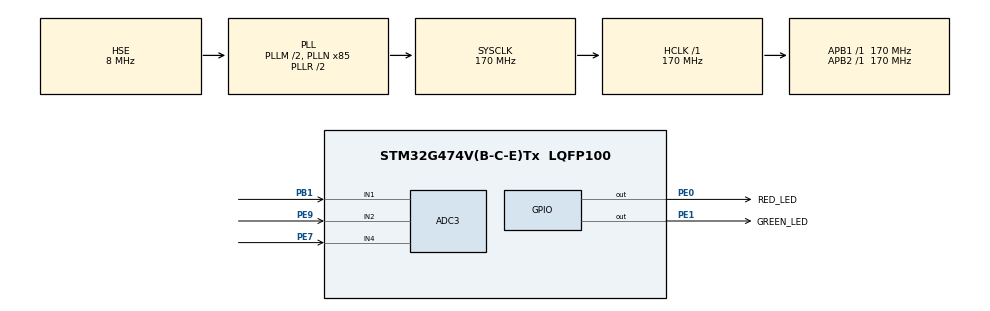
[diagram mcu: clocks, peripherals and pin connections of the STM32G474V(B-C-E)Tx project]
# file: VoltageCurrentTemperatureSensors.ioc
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ADC3.Channel-0\#ChannelRegularConversion=ADC_CHANNEL_1
ADC3.Channel-1\#ChannelRegularConversion=ADC_CHANNEL_1
ADC3.Channel-2\#ChannelRegularConversion=ADC_CHANNEL_1
ADC3.DMAContinuousRequests=ENABLE
ADC3.NbrOfConversion=3
ADC3.NbrOfConversionFlag=1
ADC3.OffsetNumber-0\#ChannelRegularConversion=ADC_OFFSET_NONE
ADC3.OffsetNumber-1\#ChannelRegularConversion=ADC_OFFSET_NONE
ADC3.OffsetNumber-2\#ChannelRegularConversion=ADC_OFFSET_NONE
ADC3.Overrun=ADC_OVR_DATA_OVERWRITTEN
ADC3.Rank-0\#ChannelRegularConversion=1
ADC3.Rank-1\#ChannelRegularConversion=2
ADC3.Rank-2\#ChannelRegularConversion=3
ADC3.SamplingTime-0\#ChannelRegularConversion=ADC_SAMPLETIME_2CYCLES_5
ADC3.SamplingTime-1\#ChannelRegularConversion=ADC_SAMPLETIME_2CYCLES_5
ADC3.SamplingTime-2\#ChannelRegularConversion=ADC_SAMPLETIME_2CYCLES_5
ADC3.master=1
Dma.ADC3.0.Direction=DMA_PERIPH_TO_MEMORY
Dma.ADC3.0.EventEnable=DISABLE
Dma.ADC3.0.Instance=DMA1_Channel1
Dma.ADC3.0.MemDataAlignment=DMA_MDATAALIGN_HALFWORD
Dma.ADC3.0.MemInc=DMA_MINC_ENABLE
Dma.ADC3.0.Mode=DMA_CIRCULAR
Dma.ADC3.0.PeriphDataAlignment=DMA_PDATAALIGN_HALFWORD
Dma.ADC3.0.PeriphInc=DMA_PINC_DISABLE
Dma.ADC3.0.Polarity=HAL_DMAMUX_REQ_GEN_RISING
Dma.ADC3.0.Priority=DMA_PRIORITY_MEDIUM
Dma.ADC3.0.RequestNumber=1
Dma.ADC3.0.SignalID=NONE
Dma.ADC3.0.SyncEnable=DISABLE
Dma.ADC3.0.SyncPolarity=HAL_DMAMUX_SYNC_NO_EVENT
Dma.ADC3.0.SyncRequestNumber=1
Dma.ADC3.0.SyncSignalID=NONE
Dma.Request0=ADC3
Mcu.Family=STM32G4
Mcu.Name=STM32G474V(B-C-E)Tx
Mcu.Package=LQFP100
NVIC.ADC3_IRQn=true\:0\:0\:false\:false\:true\:true\:true\:true
NVIC.DMA1_Channel1_IRQn=true\:0\:0\:false\:false\:true\:false\:true\:true
NVIC.PriorityGroup=NVIC_PRIORITYGROUP_4
NVIC.TIM6_DAC_IRQn=true\:0\:0\:false\:false\:true\:false\:true\:true
NVIC.TimeBase=TIM6_DAC_IRQn
NVIC.TimeBaseIP=TIM6
PB1.Mode=IN1-Single-Ended
PB1.Signal=ADC3_IN1
PE0.GPIO_Label=RED_LED
PE0.Signal=GPIO_Output
PE1.GPIO_Label=GREEN_LED
PE1.Signal=GPIO_Output
PE7.Mode=IN4-Single-Ended
PE7.Signal=ADC3_IN4
PE9.Mode=IN2-Single-Ended
PE9.Signal=ADC3_IN2
PF0-OSC_IN.Mode=HSE-External-Oscillator
PF0-OSC_IN.Signal=RCC_OSC_IN
PF1-OSC_OUT.Mode=HSE-External-Oscillator
PF1-OSC_OUT.Signal=RCC_OSC_OUT
ProjectManager.HeapSize=0x200
ProjectManager.StackSize=0x400
ProjectManager.TargetToolchain=STM32CubeIDE
RCC.ADC12Freq_Value=170000000
RCC.ADC345Freq_Value=170000000
RCC.AHBFreq_Value=170000000
RCC.APB1Freq_Value=170000000
RCC.APB1TimFreq_Value=170000000
RCC.APB2Freq_Value=170000000
RCC.APB2TimFreq_Value=170000000
RCC.CortexFreq_Value=170000000
RCC.EXTERNAL_CLOCK_VALUE=12288000
RCC.HCLKFreq_Value=170000000
RCC.HSE_VALUE=8000000
RCC.HSI48_VALUE=48000000
RCC.HSI_VALUE=16000000
RCC.LSE_VALUE=32768
RCC.PLLM=RCC_PLLM_DIV2
RCC.PLLN=85
RCC.PLLSourceVirtual=RCC_PLLSOURCE_HSE
RCC.SYSCLKFreq_VALUE=170000000
RCC.SYSCLKSource=RCC_SYSCLKSOURCE_PLLCLK
RCC.USBFreq_Value=170000000
RCC.VCOOutputFreq_Value=340000000
VP_SYS_VS_DBSignals.Mode=DisableDeadBatterySignals
VP_SYS_VS_tim6.Mode=TIM6
board=custom

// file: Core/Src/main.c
/* USER CODE BEGIN Header */
/**
  ******************************************************************************
  * @file           : main.c
  * @brief          : Main program body
  ******************************************************************************
  * @attention
  *
  * Copyright (c) 2024 STMicroelectronics.
  * All rights reserved.
  *
  * This software is licensed under terms that can be found in the LICENSE file
  * in the root directory of this software component.
  * If no LICENSE file comes with this software, it is provided AS-IS.
  *
  ******************************************************************************
  */
/* USER CODE END Header */
#include "main.h"
#include "adc.h"
#include "dma.h"
#include "gpio.h"

void SystemClock_Config(void);

int main(void)
{

  /* MCU Configuration--------------------------------------------------------*/

  /* Reset of all peripherals, Initializes the Flash interface and the Systick. */
  HAL_Init();

  /* Configure the system clock */
  SystemClock_Config();

  /* Initialize all configured peripherals */
  MX_GPIO_Init();
  MX_DMA_Init();
  MX_ADC3_Init();

  /* Infinite loop */
  /* USER CODE BEGIN WHILE */
  while (1)
  {
	  HAL_GPIO_TogglePin(RED_LED_GPIO_Port, RED_LED_Pin);
	  HAL_GPIO_TogglePin(GREEN_LED_GPIO_Port, GREEN_LED_Pin);

	  HAL_Delay(250);
    /* USER CODE END WHILE */

  }
}

void SystemClock_Config(void)
{
  RCC_OscInitTypeDef RCC_OscInitStruct = {0};
  RCC_ClkInitTypeDef RCC_ClkInitStruct = {0};

  /** Configure the main internal regulator output voltage
  */
  HAL_PWREx_ControlVoltageScaling(PWR_REGULATOR_VOLTAGE_SCALE1_BOOST);

  /** Initializes the RCC Oscillators according to the specified parameters
  * in the RCC_OscInitTypeDef structure.
  */
  RCC_OscInitStruct.OscillatorType = RCC_OSCILLATORTYPE_HSE;
  RCC_OscInitStruct.HSEState = RCC_HSE_ON;
  RCC_OscInitStruct.PLL.PLLState = RCC_PLL_ON;
  RCC_OscInitStruct.PLL.PLLSource = RCC_PLLSOURCE_HSE;
  RCC_OscInitStruct.PLL.PLLM = RCC_PLLM_DIV2;
  RCC_OscInitStruct.PLL.PLLN = 85;
  RCC_OscInitStruct.PLL.PLLP = RCC_PLLP_DIV2;
  RCC_OscInitStruct.PLL.PLLQ = RCC_PLLQ_DIV2;
  RCC_OscInitStruct.PLL.PLLR = RCC_PLLR_DIV2;
  if (HAL_RCC_OscConfig(&RCC_OscInitStruct) != HAL_OK)
  {
    Error_Handler();
  }

  /** Initializes the CPU, AHB and APB buses clocks
  */
  RCC_ClkInitStruct.ClockType = RCC_CLOCKTYPE_HCLK|RCC_CLOCKTYPE_SYSCLK
                              |RCC_CLOCKTYPE_PCLK1|RCC_CLOCKTYPE_PCLK2;
  RCC_ClkInitStruct.SYSCLKSource = RCC_SYSCLKSOURCE_PLLCLK;
  RCC_ClkInitStruct.AHBCLKDivider = RCC_SYSCLK_DIV1;
  RCC_ClkInitStruct.APB1CLKDivider = RCC_HCLK_DIV1;
  RCC_ClkInitStruct.APB2CLKDivider = RCC_HCLK_DIV1;

  if (HAL_RCC_ClockConfig(&RCC_ClkInitStruct, FLASH_LATENCY_4) != HAL_OK)
  {
    Error_Handler();
  }
}

void HAL_TIM_PeriodElapsedCallback(TIM_HandleTypeDef *htim)
{
  if (htim->Instance == TIM6) {
    HAL_IncTick();
  }
}

void Error_Handler(void)
{
  __disable_irq();
  while (1)
  {
  }
}
